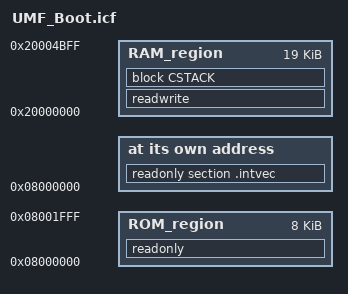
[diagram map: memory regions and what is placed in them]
/*###ICF### Section handled by ICF editor, don't touch! ****/
/*-Editor annotation file-*/
/* IcfEditorFile="$TOOLKIT_DIR$\config\ide\IcfEditor\cortex_v1_0.xml" */
/*-Specials-*/
define symbol __ICFEDIT_intvec_start__     = 0x08000000;
/*-Memory Regions-*/
/* UMF Bootloader link regions (plan v3.2 sec.3, amended by gate G1-d):
 *   ROM = Page 0..7 (0x08000000..0x08001FFF), 8,192 B.
 *   Page 8 (backup) / Page 9..60 (App) / Page 61..63 (params) are all
 *   outside the BL link region.
 *   G1-d amendment: the original 6 KB region was exceeded at first full
 *   build (7,480 B total with size optimization), see BL update log D7.
 *   RAM matches the App project: linked 0x20000000..0x20004BFF; the shared
 *   mailbox at 0x20004C00..0x20004DFF is linked by NEITHER image (plan
 *   v3.2 sec.5.2, survives warm reset). */
define symbol __ICFEDIT_region_ROM_start__ = 0x08000000;
define symbol __ICFEDIT_region_ROM_end__   = 0x08001FFF;
define symbol __ICFEDIT_region_RAM_start__ = 0x20000000;
define symbol __ICFEDIT_region_RAM_end__   = 0x20004BFF;
/*-Sizes-*/
/* BL runtime RAM budget ~2.5 KB (plan v3.2 sec.2.3): 1 KB stack, no heap. */
define symbol __ICFEDIT_size_cstack__ = 0x400;
define symbol __ICFEDIT_size_heap__   = 0x0;
/**** End of ICF editor section. ###ICF###***/

define memory mem with size = 4G;
define region ROM_region = mem:[from __ICFEDIT_region_ROM_start__   to __ICFEDIT_region_ROM_end__];
define region RAM_region = mem:[from __ICFEDIT_region_RAM_start__   to __ICFEDIT_region_RAM_end__];

define block CSTACK with alignment = 8, size = __ICFEDIT_size_cstack__ { };

initialize by copy { readwrite };
do not initialize  { section .noinit };

place at address mem:__ICFEDIT_intvec_start__ { readonly section .intvec };

place in ROM_region { readonly };
place in RAM_region { readwrite, block CSTACK };
